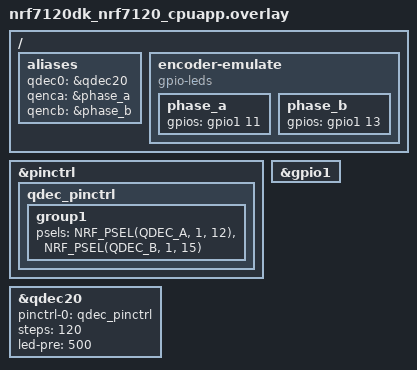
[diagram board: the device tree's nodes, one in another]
/*
 * Copyright (c) 2025 Nordic Semiconductor ASA
 *
 * SPDX-License-Identifier: Apache-2.0
 */

/ {
	aliases {
		qdec0 = &qdec20;
		qenca = &phase_a;
		qencb = &phase_b;
	};

	encoder-emulate {
		compatible = "gpio-leds";

		phase_a: phase_a {
			gpios = <&gpio1 11 GPIO_ACTIVE_HIGH>;
		};

		phase_b: phase_b {
			gpios = <&gpio1 13 GPIO_ACTIVE_HIGH>;
		};
	};
};

&pinctrl {
	qdec_pinctrl: qdec_pinctrl {
		group1 {
			psels = <NRF_PSEL(QDEC_A, 1, 12)>,
				<NRF_PSEL(QDEC_B, 1, 15)>;
		};
	};
};

&gpio1 {
	status = "okay";
};

&qdec20 {
	status = "okay";
	pinctrl-0 = <&qdec_pinctrl>;
	pinctrl-names = "default";
	steps = <120>;
	led-pre = <500>;
};
